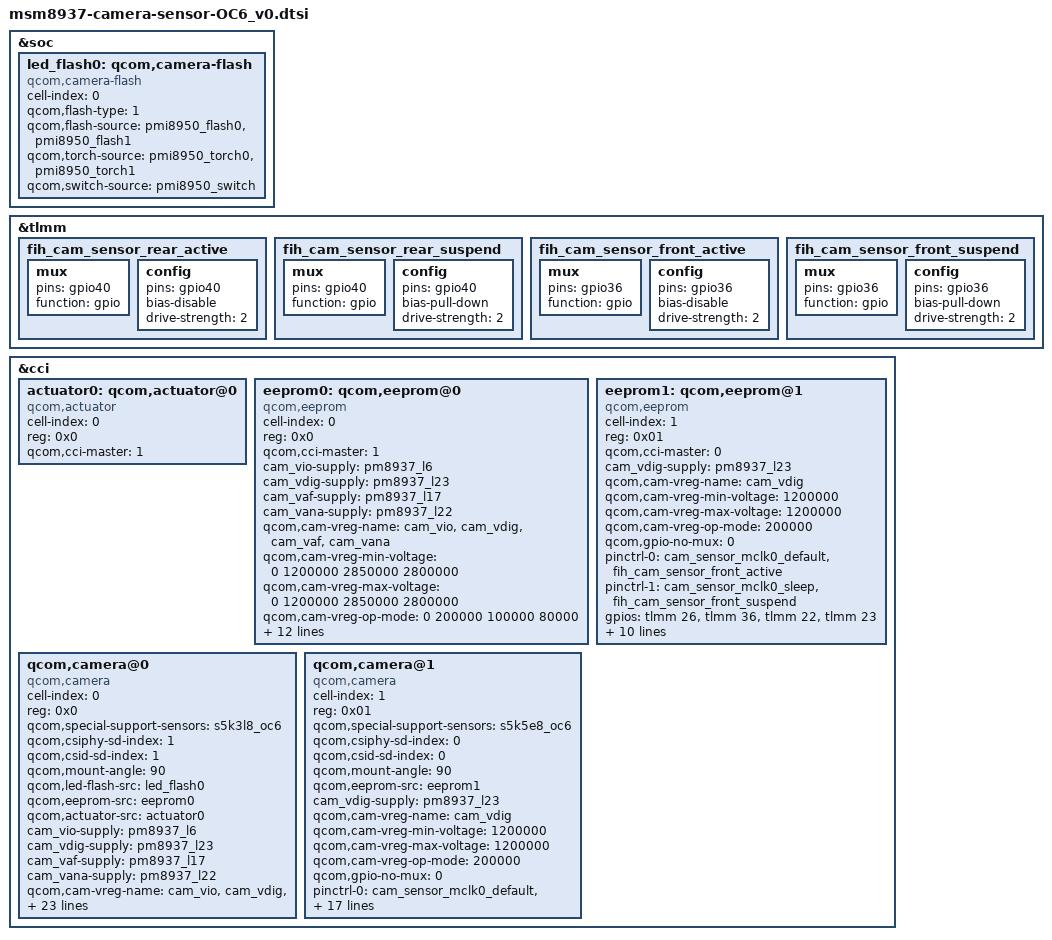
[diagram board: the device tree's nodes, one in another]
/*
 * Copyright (c) 2015-2016, The Linux Foundation. All rights reserved.
 *
 * This program is free software; you can redistribute it and/or modify
 * it under the terms of the GNU General Public License version 2 and
 * only version 2 as published by the Free Software Foundation.
 *
 * This program is distributed in the hope that it will be useful,
 * but WITHOUT ANY WARRANTY; without even the implied warranty of
 * MERCHANTABILITY or FITNESS FOR A PARTICULAR PURPOSE.  See the
 * GNU General Public License for more details.
 */

&soc {
	led_flash0: qcom,camera-flash {
		cell-index = <0>;
		compatible = "qcom,camera-flash";
		qcom,flash-type = <1>;
		qcom,flash-source = <&pmi8950_flash0 &pmi8950_flash1>;
		qcom,torch-source = <&pmi8950_torch0 &pmi8950_torch1>;
		qcom,switch-source = <&pmi8950_switch>;
	};
};

&tlmm {
		fih_cam_sensor_rear_active: fih_cam_sensor_rear_active {
			/* RESET */
			mux {
				pins = "gpio40";
				function = "gpio";
			};

			config {
				pins = "gpio40";
				bias-disable; /* No PULL */
				drive-strength = <2>; /* 2 MA */
			};
		};

		fih_cam_sensor_rear_suspend: fih_cam_sensor_rear_suspend {
			/* RESET */
			mux {
				pins = "gpio40";
				function = "gpio";
			};

			config {
				pins = "gpio40";
				bias-pull-down; /* PULL DOWN */
				drive-strength = <2>; /* 2 MA */
			};
		};

		fih_cam_sensor_front_active: fih_cam_sensor_front_active {
			/* RESET */
			mux {
				pins = "gpio36";
				function = "gpio";
			};

			config {
				pins = "gpio36";
				bias-disable; /* No PULL */
				drive-strength = <2>; /* 2 MA */
			};
		};

		fih_cam_sensor_front_suspend: fih_cam_sensor_front_suspend {
			/* RESET */
			mux {
				pins = "gpio36";
				function = "gpio";
			};

			config {
				pins = "gpio36";
				bias-pull-down; /* PULL DOWN */
				drive-strength = <2>; /* 2 MA */
			};
		};
};

&cci {

  /delete-node/ qcom,actuator@0;
  /delete-node/ qcom,actuator@1;
  /delete-node/ qcom,eeprom@0;
  /delete-node/ qcom,eeprom@1;
	/delete-node/ qcom,camera@0;
	/delete-node/ qcom,camera@1;
	/delete-node/ qcom,camera@2;

	actuator0: qcom,actuator@0 {
		cell-index = <0>;
		reg = <0x0>;
		compatible = "qcom,actuator";
		qcom,cci-master = <1>;
/*
		cam_vaf-supply = <&pm8937_l17>;
		qcom,cam-vreg-name = "cam_vaf";
		qcom,cam-vreg-min-voltage = <2850000>;
		qcom,cam-vreg-max-voltage = <2850000>;
		qcom,cam-vreg-op-mode = <80000>;
*/
	};

	eeprom0: qcom,eeprom@0 {
		cell-index = <0>;
		reg = <0x0>;
		compatible = "qcom,eeprom";
		qcom,cci-master = <1>;

/*		qcom,eeprom-name = "s5k3l8_oc6"; */
/*		qcom,slave-addr = <0x5a>;   */

		cam_vio-supply = <&pm8937_l6>;
		cam_vdig-supply = <&pm8937_l23>;
		cam_vaf-supply = <&pm8937_l17>;
		cam_vana-supply = <&pm8937_l22>;
		qcom,cam-vreg-name = "cam_vio", "cam_vdig", "cam_vaf", "cam_vana";
		qcom,cam-vreg-min-voltage = <0 1200000 2850000 2800000>;
		qcom,cam-vreg-max-voltage = <0 1200000 2850000 2800000>;
		qcom,cam-vreg-op-mode = <0 200000 100000 80000>;
		pinctrl-names = "cam_default", "cam_suspend";
		pinctrl-0 = <&cam_sensor_mclk2_default
				&fih_cam_sensor_rear_active>;
		pinctrl-1 = <&cam_sensor_mclk2_sleep &fih_cam_sensor_rear_suspend>;
		gpios = <&tlmm 28 0>,
			<&tlmm 40 0>;
		qcom,gpio-reset = <1>;
		qcom,gpio-req-tbl-num = <0 1>;
		qcom,gpio-req-tbl-flags = <1 0>;
		qcom,gpio-req-tbl-label = "EP_MCLK2",
			"EP_2_RST";

		status = "ok";
		clocks = <&clock_gcc clk_mclk2_clk_src>,
				<&clock_gcc clk_gcc_camss_mclk2_clk>;
		clock-names = "cam_src_clk", "cam_clk";
		qcom,clock-rates = <24000000 0>;
	};

	eeprom1: qcom,eeprom@1 {
		cell-index = <1>;
		reg = <0x01>;
		compatible = "qcom,eeprom";
		qcom,cci-master = <0>;

		cam_vdig-supply = <&pm8937_l23>;
		qcom,cam-vreg-name = "cam_vdig";
		qcom,cam-vreg-min-voltage = <1200000>;
		qcom,cam-vreg-max-voltage = <1200000>;
		qcom,cam-vreg-op-mode = <200000>;
		qcom,gpio-no-mux = <0>;
		pinctrl-names = "cam_default", "cam_suspend";
		pinctrl-0 = <&cam_sensor_mclk0_default
				&fih_cam_sensor_front_active>;
		pinctrl-1 = <&cam_sensor_mclk0_sleep
				&fih_cam_sensor_front_suspend>;
		gpios = <&tlmm 26 0>,
			<&tlmm 36 0>,
			<&tlmm 22 0>,
			<&tlmm 23 0>;
		qcom,gpio-reset = <1>;
		qcom,gpio-vana = <2>;
		qcom,gpio-vio = <3>;
		qcom,gpio-req-tbl-num = <0 1 2 3>;
		qcom,gpio-req-tbl-flags = <1 0 0 0>;
		qcom,gpio-req-tbl-label = "EP_MCLK0",
			"EP_1_RST",
			"EP_2P8_EN",
			"EP_1P8_EN";

		status = "ok";
		clocks = <&clock_gcc clk_mclk0_clk_src>,
				<&clock_gcc clk_gcc_camss_mclk0_clk>;
		clock-names = "cam_src_clk", "cam_clk";
		qcom,clock-rates = <24000000 0>;
	};

	qcom,camera@0 {
		cell-index = <0>;
		compatible = "qcom,camera";
		reg = <0x0>;
		qcom,special-support-sensors = "s5k3l8_oc6";
		qcom,csiphy-sd-index = <1>;
		qcom,csid-sd-index = <1>;
		qcom,mount-angle = <90>;
		qcom,led-flash-src = <&led_flash0>;
		qcom,eeprom-src = <&eeprom0>;
		qcom,actuator-src = <&actuator0>;
		cam_vio-supply = <&pm8937_l6>;
		cam_vdig-supply = <&pm8937_l23>;
		cam_vaf-supply = <&pm8937_l17>;
		cam_vana-supply = <&pm8937_l22>;
		qcom,cam-vreg-name = "cam_vio", "cam_vdig", "cam_vaf", "cam_vana";
		qcom,cam-vreg-min-voltage = <0 1200000 2850000 2800000>;
		qcom,cam-vreg-max-voltage = <0 1200000 2850000 2800000>;
		qcom,cam-vreg-op-mode = <0 200000 100000 80000>;
		pinctrl-names = "cam_default", "cam_suspend";
		pinctrl-0 = <&cam_sensor_mclk2_default
				&fih_cam_sensor_rear_active>;
		pinctrl-1 = <&cam_sensor_mclk2_sleep &fih_cam_sensor_rear_suspend>;
		gpios = <&tlmm 28 0>,
			<&tlmm 40 0>,
			<&tlmm 41 0>;
		qcom,gpio-reset = <1>;
		qcom,gpio-vio = <2>;
		qcom,gpio-req-tbl-num = <0 1 2>;
		qcom,gpio-req-tbl-flags = <1 0 0>;
		qcom,gpio-req-tbl-label = "CAMIF_MCLK2",
			"CAM_2_RST",
			"CAM_SID";
		qcom,sensor-position = <0>;
		qcom,sensor-mode = <0>;
		qcom,cci-master = <1>;
		status = "ok";
		clocks = <&clock_gcc clk_mclk2_clk_src>,
				<&clock_gcc clk_gcc_camss_mclk2_clk>;
		clock-names = "cam_src_clk", "cam_clk";
		qcom,clock-rates = <24000000 0>;
	};

	qcom,camera@1 {
		cell-index = <1>;
		compatible = "qcom,camera";
		reg = <0x01>;
		qcom,special-support-sensors = "s5k5e8_oc6";
		qcom,csiphy-sd-index = <0>;
		qcom,csid-sd-index = <0>;
		qcom,mount-angle = <90>;
		qcom,eeprom-src = <&eeprom1>;
		cam_vdig-supply = <&pm8937_l23>;
		qcom,cam-vreg-name = "cam_vdig";
		qcom,cam-vreg-min-voltage = <1200000>;
		qcom,cam-vreg-max-voltage = <1200000>;
		qcom,cam-vreg-op-mode = <200000>;
		qcom,gpio-no-mux = <0>;
		pinctrl-names = "cam_default", "cam_suspend";
		pinctrl-0 = <&cam_sensor_mclk0_default
				&fih_cam_sensor_front_active>;
		pinctrl-1 = <&cam_sensor_mclk0_sleep
				&fih_cam_sensor_front_suspend>;
		gpios = <&tlmm 26 0>,
			<&tlmm 36 0>,
			<&tlmm 22 0>,
			<&tlmm 23 0>;
		qcom,gpio-reset = <1>;
		qcom,gpio-vana = <2>;
		qcom,gpio-vio = <3>;
		qcom,gpio-req-tbl-num = <0 1 2 3>;
		qcom,gpio-req-tbl-flags = <1 0 0 0>;
		qcom,gpio-req-tbl-label = "CAMIF_MCLK0",
			"CAM_1_RST",
			"CAM_2P8_EN",
			"CAM_1P8_EN";
		qcom,sensor-position = <1>;
		qcom,sensor-mode = <0>;
		qcom,cci-master = <0>;
		status = "ok";
		clocks = <&clock_gcc clk_mclk0_clk_src>,
				<&clock_gcc clk_gcc_camss_mclk0_clk>;
		clock-names = "cam_src_clk", "cam_clk";
		qcom,clock-rates = <24000000 0>;
	};
};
